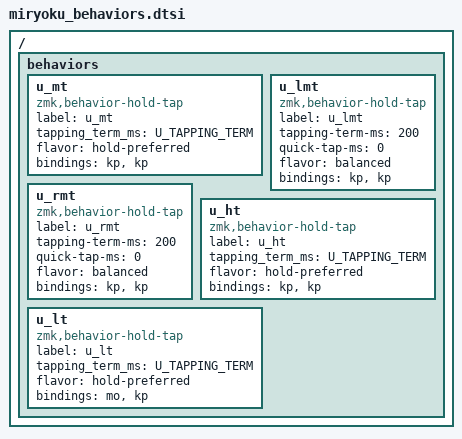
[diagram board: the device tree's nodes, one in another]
// Copyright 2022 Manna Harbour
// https://github.com/manna-harbour/miryoku

/ {
  behaviors {
    u_mt: u_mt {
      compatible = "zmk,behavior-hold-tap";
      label = "u_mt";
      #binding-cells = <2>;
      tapping_term_ms = <U_TAPPING_TERM>;
      flavor = "hold-preferred";
      bindings = <&kp>, <&kp>;
    };
    u_lmt: u_lmt {
      compatible = "zmk,behavior-hold-tap";
      label = "u_lmt";
      #binding-cells = <2>;
            tapping-term-ms = <200>;
            quick-tap-ms = <0>;
            flavor = "balanced";
      bindings = <&kp>, <&kp>;
    };
    u_rmt: u_rmt {
      compatible = "zmk,behavior-hold-tap";
      label = "u_rmt";
      #binding-cells = <2>;
            tapping-term-ms = <200>;
            quick-tap-ms = <0>;
            flavor = "balanced";
      bindings = <&kp>, <&kp>;
    };
    u_ht: u_ht {
      compatible = "zmk,behavior-hold-tap";
      label = "u_ht";
      #binding-cells = <2>;
      tapping_term_ms = <U_TAPPING_TERM>;
      flavor = "hold-preferred";
      bindings = <&kp>, <&kp>;
    };
    u_lt: u_lt {
      compatible = "zmk,behavior-hold-tap";
      label = "u_lt";
      #binding-cells = <2>;
      tapping_term_ms = <U_TAPPING_TERM>;
      flavor = "hold-preferred";
      bindings = <&mo>, <&kp>;
    };
  };
};
